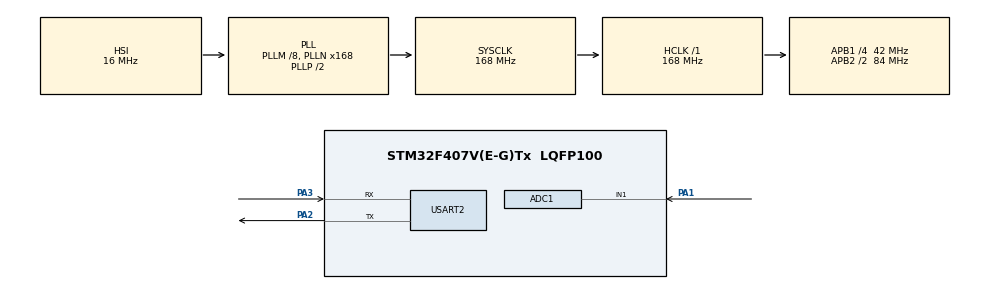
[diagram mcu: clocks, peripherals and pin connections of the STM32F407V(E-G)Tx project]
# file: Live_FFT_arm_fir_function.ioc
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ADC1.Channel-5\#ChannelRegularConversion=ADC_CHANNEL_1
ADC1.ContinuousConvMode=DISABLE
ADC1.NbrOfConversionFlag=1
ADC1.Rank-5\#ChannelRegularConversion=1
ADC1.SamplingTime-5\#ChannelRegularConversion=ADC_SAMPLETIME_3CYCLES
ADC1.master=1
Mcu.Family=STM32F4
Mcu.Name=STM32F407V(E-G)Tx
Mcu.Package=LQFP100
NVIC.PriorityGroup=NVIC_PRIORITYGROUP_0
PA1.Signal=ADCx_IN1
PA2.Mode=Asynchronous
PA2.Signal=USART2_TX
PA3.Mode=Asynchronous
PA3.Signal=USART2_RX
PH0-OSC_IN.Mode=HSE-External-Oscillator
PH0-OSC_IN.Signal=RCC_OSC_IN
PH1-OSC_OUT.Mode=HSE-External-Oscillator
PH1-OSC_OUT.Signal=RCC_OSC_OUT
ProjectManager.HeapSize=0x200
ProjectManager.StackSize=0x400
ProjectManager.TargetToolchain=STM32CubeIDE
RCC.48MHZClocksFreq_Value=48000000
RCC.AHBFreq_Value=168000000
RCC.APB1CLKDivider=RCC_HCLK_DIV4
RCC.APB1Freq_Value=42000000
RCC.APB1TimFreq_Value=84000000
RCC.APB2CLKDivider=RCC_HCLK_DIV2
RCC.APB2Freq_Value=84000000
RCC.APB2TimFreq_Value=168000000
RCC.CortexFreq_Value=168000000
RCC.HCLKFreq_Value=168000000
RCC.HSE_VALUE=8000000
RCC.HSI_VALUE=16000000
RCC.LSE_VALUE=32768
RCC.PLLM=8
RCC.PLLN=168
RCC.PLLQ=7
RCC.SYSCLKFreq_VALUE=168000000
RCC.SYSCLKSource=RCC_SYSCLKSOURCE_PLLCLK
RCC.VCOOutputFreq_Value=336000000
SH.ADCx_IN1.0=ADC1_IN1,IN1
USART2.VirtualMode=VM_ASYNC
board=STM32F407G-DISC1

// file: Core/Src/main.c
/* USER CODE BEGIN Header */
/**
  ******************************************************************************
  * @file           : main.c
  * @brief          : Main program body
  ******************************************************************************
  * @attention
  *
  * Copyright (c) 2026 STMicroelectronics.
  * All rights reserved.
  *
  * This software is licensed under terms that can be found in the LICENSE file
  * in the root directory of this software component.
  * If no LICENSE file comes with this software, it is provided AS-IS.
  *
  ******************************************************************************
  */
/* USER CODE END Header */
#include "main.h"
#include "adc.h"
#include "usart.h"
#include "gpio.h"

/* USER CODE BEGIN Includes */
//#include "stm32f407xx.h"
#include "signals.h"
#include "stdio.h"
#include "arm_math.h"
#include <math.h>
#include "stdlib.h"
#include "fifo.h"
/* USER CODE END Includes */

/* USER CODE BEGIN PTD */

#define FILTER_Taps fir_len

/* ===== ARM fir_function ===== */
#define NUM_TAPS   fir_len
#define BLOCK_SIZE live_ecg_len

arm_fir_instance_f32 firFilter;
float32_t firState[NUM_TAPS + BLOCK_SIZE - 1];
/* ========================== */

#define input_sig_len live_ecg_len
#define filter_len fir_len

extern const float32_t  _640_points_ecg_[sig_ecg_len];
extern const float32_t ecg_mudy_sig[ECG_mudy_len];
extern const float32_t fir_filter[fir_len];

extern volatile uint8_t sample_tick;

/* ---- Compile-time "round up to next power of two" -------------------------
 * Classic bit-smearing trick: OR each bit down into all bits below it, then
 * add 1. Works purely with constant arithmetic, so the result can be used
 * as an array size. */
#define _B2(x)   ( (x)      | ((x) >> 1)  )
#define _B4(x)   ( _B2(x)   | (_B2(x) >> 2)  )
#define _B8(x)   ( _B4(x)   | (_B4(x) >> 4)  )
#define _B16(x)  ( _B8(x)   | (_B8(x) >> 8)  )
#define _B32(x)  ( _B16(x)  | (_B16(x) >> 16) )
#define NEXT_POW2(x)  (_B32((x) - 1) + 1)

/* ===== OR ===== */

//uint32_t next_power_of_2(uint32_t x)
//{
//    if (x == 0) return 1;
//
//    x = x - 1;          // step 1: back off by one (so exact powers of 2 stay unchanged)
//
//    // step 2: "smear" the highest set bit downward into every bit below it,
//    // by repeatedly OR-ing the number with a right-shifted copy of itself
//    x = x | (x >> 1);
//    x = x | (x >> 2);
//    x = x | (x >> 4);
//    x = x | (x >> 8);
//    x = x | (x >> 16);
//    // at this point x is all 1-bits, e.g. 0b00011111 (31)
//
//    x = x + 1;           // step 3: turn "all 1s" into the actual power of two
//
//    return x;
//}

/* Length needed for a full ("linear") convolution of the ECG signal with the
 * FIR filter: len(x) + len(h) - 1.
 *
 * NOTE: renamed from the original "L" to "LINEAR_CONV_LEN". A macro named
 * "L" would have been substituted INSIDE the prototype
 * "uint32_t next_power_of_2(uint32_t L)" below, mangling the parameter name -
 * a subtle bug waiting to happen even after fixing the file-scope issue. */
#define LINEAR_CONV_LEN  (input_sig_len + filter_len - 1)

/* Smallest power-of-two FFT length that can hold the full linear convolution
 * without circular-convolution wrap-around (this is a classic
 * overlap-save / fast-convolution-via-FFT length requirement). Computed at
 * compile time now - no more runtime "fft_len" needed for sizing. */
#define FFT_BUFFER_SIZE  NEXT_POW2(LINEAR_CONV_LEN)

/* arm_rfft_fast_f32 (CMSIS-DSP, f32 variant) only supports power-of-two
 * lengths from 32 to 4096. Catch an unsupported combination of signal /
 * filter lengths at BUILD time instead of arm_rfft_fast_init_f32() silently
 * returning an error status at runtime. */
//#if (FFT_BUFFER_SIZE < 32) || (FFT_BUFFER_SIZE > 4096)
//#error "FFT_BUFFER_SIZE is outside the range supported by arm_rfft_fast_f32 (32-4096). Check input_sig_len/filter_len in signals.h."
//#endif

float32_t padded_filter[FFT_BUFFER_SIZE];
float32_t padded_filter2[FFT_BUFFER_SIZE];
float32_t FFT_Buff_In[FFT_BUFFER_SIZE];
float32_t FFT_Buff_In2[FFT_BUFFER_SIZE];
float32_t FFT_Buff_Out[FFT_BUFFER_SIZE];
float32_t FFT_Buff_Out_original[LINEAR_CONV_LEN];
float32_t conv_out[LINEAR_CONV_LEN];
float32_t conv_out_aligned[input_sig_len];   /* group-delay-compensated, same length as input */

float32_t fft_time_result[FFT_BUFFER_SIZE];

#define GROUP_DELAY  ((filter_len - 1) / 2)

/* Time-aligned filtered output: FFT_Buff_Out_original[n + GROUP_DELAY] is
 * what actually corresponds to input sample n, once the filter's inherent
 * delay is removed. Same length as the input signal, so it plots directly
 * against ecg_mudy_sig sample-for-sample with no offset. */
float32_t FFT_Buff_Out_aligned[input_sig_len];
/* USER CODE END PTD */

/* USER CODE BEGIN PD */

void plot_signal(float32_t *arr,uint32_t sign_len);
arm_rfft_fast_instance_f32 fftHandler;

static uint16_t format_sample(float32_t sample, char *dst, uint16_t dst_size);
void plot_signal_2(float32_t *arr1, uint32_t len1, float32_t *arr2, uint32_t len2);
 void plot_signal_3(float32_t *arr1, uint32_t len1, float32_t *arr2, uint32_t len2,float32_t *arr3, uint32_t len3);

/* USER CODE END PD */

void SystemClock_Config(void);

/* USER CODE BEGIN 0 */

/* ===== Fifo variables ===== */
volatile uint8_t  flag = 0;
uint32_t sample_count = 0;
volatile uint32_t fifo_overflow_count = 0;   /* FIFO was full when a sample arrived */
volatile uint32_t adc_timeout_count   = 0;   /* ADC didn't finish converting in time */

uint16_t val = 0; //rx_DataType
rx_DataType rx_data;
#define adc_buff_len 500
rx_DataType adc_buff[adc_buff_len];   /* same type as the FIFO holds */

uint32_t adc_ready = 0;
char bf[10];
/* ===== END ===== */

void reduce_to_original_len(float32_t *output_buff)
{
    for (uint32_t i = 0; i < LINEAR_CONV_LEN; i++)
	{
        FFT_Buff_Out_original[i] = output_buff[i];
	}
}
/* ===== Systick CallBack ===== */
//void HAL_SYSTICK_Callback(void)
//{
//	if(!adc_ready)
//	{
//		return;
//	}
//    if (HAL_ADC_Start(&hadc1) != HAL_OK)
//    {
//        return;
//    }
//
//    if (HAL_ADC_PollForConversion(&hadc1, 1) == HAL_OK)
//    {
//        val = (rx_DataType)HAL_ADC_GetValue(&hadc1);
//
//        if (rx_fifo_put(val) == RXFIFO_Done)
//        {
//            sample_count++;
//            if (sample_count >= adc_buff_len)
//            {
//                flag = 1;
//                sample_count = 0;
//            }
//        }
//        else
//        {
//            fifo_overflow_count++;   /* main loop is draining too slowly */
//        }
//    }
//    else
//    {
//        adc_timeout_count++;         /* diagnostic only — should stay 0 */
//    }
//}
/* ===== END ===== */
float32_t block_in[BLOCK_SIZE], block_out[BLOCK_SIZE];
volatile float32_t swv_fir_sample;
/* USER CODE END 0 */

int main(void)
{

  /* MCU Configuration--------------------------------------------------------*/

  /* Reset of all peripherals, Initializes the Flash interface and the Systick. */
  HAL_Init();

  /* Configure the system clock */
  SystemClock_Config();

  /* Initialize all configured peripherals */
  MX_GPIO_Init();
  MX_USART2_UART_Init();
  MX_ADC1_Init();
  /* USER CODE BEGIN 2 */

  rx_fifo_init();

  /* USER CODE END 2 */

  /* Infinite loop */
  /* USER CODE BEGIN WHILE */

  //HAL_ADC_Start_IT(&hadc1);

      adc_ready = 1;

 arm_fir_init_f32(&firFilter, NUM_TAPS, (float32_t *)fir_filter, firState, BLOCK_SIZE);

  while (1)
  {
    /* USER CODE END WHILE */

    /* USER CODE BEGIN 3 */
	  if(sample_tick)
	  {
		  sample_tick = 0;

	        if (HAL_ADC_Start(&hadc1) == HAL_OK &&
	            HAL_ADC_PollForConversion(&hadc1, 1) == HAL_OK)
	        {
	            val = (rx_DataType)HAL_ADC_GetValue(&hadc1);
	            if (rx_fifo_put(val) == RXFIFO_Done)
	            {
	                sample_count++;
	                if (sample_count >= adc_buff_len)
	                {
	                    flag = 1;
	                    sample_count = 0;
	                }
	            }
	            else { fifo_overflow_count++; }
	        }
	        else { adc_timeout_count++; }

	  }
	  /* ===== ADC buffer fill ===== */

	  if (flag == 1)
	 	      {
	 	          int received = 0;

	 	          for (int i = 0; i < adc_buff_len; i++)
	 	          {
	 	              if (rx_fifo_get(&rx_data) == RXFIFO_Done)
	 	              {
	 	                  adc_buff[i] = rx_data;
	 	                  received++;
	 	              }
	 	              else
	 	              {
	 	                  break;
	 	              }
	 	          }

//	 	          for (int i = 0; i < received; i++)
//	 	          {
//	 	              sprintf(bf, "%d\r\n", adc_buff[i]);
//	 	              HAL_UART_Transmit(&huart2, (uint8_t *)bf, strlen(bf), HAL_MAX_DELAY);
//	 	          }

	 	        for (uint32_t i = 0; i < BLOCK_SIZE; i++)

	 	        	{
	 	        	block_in[i] = (float32_t)adc_buff[i];
	 	        	}

	 	        arm_fir_f32(&firFilter,block_in,block_out,BLOCK_SIZE);

//for(int j = 0;j<BLOCK_SIZE;j++)
//{
//	swv_fir_sample = block_out[j];
//}
		          /* ===== Plotting ===== */
	 	       for (uint32_t i = 0; i < BLOCK_SIZE; i++)
	 	              {
	 	                  char tx_buf[128];

	 	                  snprintf(
	 	                      tx_buf,
	 	                      sizeof(tx_buf),
	 	                      "%.5f,%.5f\r\n",
	 	                      block_in[i],
	 	                      block_out[i]
	 	                  );

	 	                  HAL_UART_Transmit(
	 	                      &huart2,
	 	                      (uint8_t *)tx_buf,
	 	                      strlen(tx_buf),
	 	                      HAL_MAX_DELAY
	 	                  );
	 	              }

	 	            // plot_signal((float32_t*)adc_buff,adc_buff_len);
		           // plot_signal_2((float32_t*)adc_buff, adc_buff_len,block_out ,BLOCK_SIZE );
		         // plot_signal_3(ecg_mudy_sig, input_sig_len, conv_out_aligned,input_sig_len,FFT_Buff_Out_aligned, input_sig_len );

	 	          flag = 0;
	 	      }
	 	    }

	  /* ===== ADC Testing Code ===== */

//	  HAL_ADC_Start(&hadc1);
//	  HAL_ADC_PollForConversion(&hadc1, 1);
//	  val = HAL_ADC_GetValue(&hadc1);
//      sprintf(bf, "%d\r\n", val);
//      HAL_UART_Transmit(&huart2, (uint8_t *)bf, strlen(bf), HAL_MAX_DELAY);

	 /* ===== END ===== */

  /* USER CODE END 3 */
}

void SystemClock_Config(void)
{
  RCC_OscInitTypeDef RCC_OscInitStruct = {0};
  RCC_ClkInitTypeDef RCC_ClkInitStruct = {0};

  /** Configure the main internal regulator output voltage
  */
  __HAL_RCC_PWR_CLK_ENABLE();
  __HAL_PWR_VOLTAGESCALING_CONFIG(PWR_REGULATOR_VOLTAGE_SCALE1);

  /** Initializes the RCC Oscillators according to the specified parameters
  * in the RCC_OscInitTypeDef structure.
  */
  RCC_OscInitStruct.OscillatorType = RCC_OSCILLATORTYPE_HSI;
  RCC_OscInitStruct.HSIState = RCC_HSI_ON;
  RCC_OscInitStruct.HSICalibrationValue = RCC_HSICALIBRATION_DEFAULT;
  RCC_OscInitStruct.PLL.PLLState = RCC_PLL_ON;
  RCC_OscInitStruct.PLL.PLLSource = RCC_PLLSOURCE_HSI;
  RCC_OscInitStruct.PLL.PLLM = 8;
  RCC_OscInitStruct.PLL.PLLN = 168;
  RCC_OscInitStruct.PLL.PLLP = RCC_PLLP_DIV2;
  RCC_OscInitStruct.PLL.PLLQ = 7;
  if (HAL_RCC_OscConfig(&RCC_OscInitStruct) != HAL_OK)
  {
    Error_Handler();
  }

  /** Initializes the CPU, AHB and APB buses clocks
  */
  RCC_ClkInitStruct.ClockType = RCC_CLOCKTYPE_HCLK|RCC_CLOCKTYPE_SYSCLK
                              |RCC_CLOCKTYPE_PCLK1|RCC_CLOCKTYPE_PCLK2;
  RCC_ClkInitStruct.SYSCLKSource = RCC_SYSCLKSOURCE_PLLCLK;
  RCC_ClkInitStruct.AHBCLKDivider = RCC_SYSCLK_DIV1;
  RCC_ClkInitStruct.APB1CLKDivider = RCC_HCLK_DIV4;
  RCC_ClkInitStruct.APB2CLKDivider = RCC_HCLK_DIV2;

  if (HAL_RCC_ClockConfig(&RCC_ClkInitStruct, FLASH_LATENCY_5) != HAL_OK)
  {
    Error_Handler();
  }
}

/* USER CODE BEGIN 4 */
void plot_signal(float32_t *arr, uint32_t sig_len)
{
    char tx_buf[32];
    uint16_t len;

   // sig_len = sig_len / 2;

    for (uint32_t i = 0; i < sig_len; i++)
    {
        long val = (long)(arr[i] * 100000.0f);
        long int_part  = val / 100000;
        long frac_part = labs(val % 100000);

        if (val < 0 && int_part == 0) {
            len = snprintf(tx_buf, sizeof(tx_buf), "-%ld.%05ld\r\n", int_part, frac_part);
        } else {
            len = snprintf(tx_buf, sizeof(tx_buf), "%ld.%05ld\r\n", int_part, frac_part);
        }

        HAL_UART_Transmit(&huart2, (uint8_t*)tx_buf, len, HAL_MAX_DELAY);
        HAL_Delay(50);
    }
}
static uint16_t format_sample(float32_t sample, char *dst, uint16_t dst_size)
{
    long val = (long)(sample * 100000.0f);
    long int_part  = val / 100000;
    long frac_part = labs(val % 100000);

    if (val < 0 && int_part == 0) {
        return snprintf(dst, dst_size, "-%ld.%05ld", int_part, frac_part);
    } else {
        return snprintf(dst, dst_size, "%ld.%05ld", int_part, frac_part);
    }
}
void plot_signal_2(float32_t *arr1, uint32_t len1, float32_t *arr2, uint32_t len2)
{
    char tx_buf[40];
    char val_buf[16];
    uint16_t len;
    uint32_t max_len = (len1 > len2) ? len1 : len2;

    for (uint32_t i = 0; i < max_len; i++)
    {
        if (i < len1) {
            format_sample(arr1[i], val_buf, sizeof(val_buf));
        } else {
            val_buf[0] = '\0';   // ran out of samples for signal 1 - leave blank
        }
        len = snprintf(tx_buf, sizeof(tx_buf), "%s,", val_buf);

        if (i < len2) {
            format_sample(arr2[i], val_buf, sizeof(val_buf));
        } else {
            val_buf[0] = '\0';   // ran out of samples for signal 2 - leave blank
        }
        len += snprintf(tx_buf + len, sizeof(tx_buf) - len, "%s\r\n", val_buf);

        HAL_UART_Transmit(&huart2, (uint8_t*)tx_buf, len, HAL_MAX_DELAY);
        HAL_Delay(50);
    }
}
void plot_signal_3(float32_t *arr1, uint32_t len1,
                  float32_t *arr2, uint32_t len2,
                  float32_t *arr3, uint32_t len3)
{
    char tx_buf[80];
    char val_buf[24];
    uint16_t len;

    uint32_t max_len = len1;

    if (len2 > max_len)
        max_len = len2;

    if (len3 > max_len)
        max_len = len3;

    for (uint32_t i = 0; i < max_len; i++)
    {
        len = 0;

        /* Signal 1 */
        if (i < len1)
        {
            format_sample(arr1[i], val_buf, sizeof(val_buf));
            len += snprintf(tx_buf + len,
                            sizeof(tx_buf) - len,
                            "%s,", val_buf);
        }

        /* Signal 2 */
        if (i < len2)
        {
            format_sample(arr2[i], val_buf, sizeof(val_buf));
            len += snprintf(tx_buf + len,
                            sizeof(tx_buf) - len,
                            "%s,", val_buf);
        }

        /* Signal 3 */
        if (i < len3)
        {
            format_sample(arr3[i], val_buf, sizeof(val_buf));
            len += snprintf(tx_buf + len,
                            sizeof(tx_buf) - len,
                            "%s", val_buf);
        }

        /* New line */
        len += snprintf(tx_buf + len,
                        sizeof(tx_buf) - len,
                        "\r\n");

        HAL_UART_Transmit(&huart2,
                          (uint8_t *)tx_buf,
                          len,
                          HAL_MAX_DELAY);

        HAL_Delay(50);
    }
}

/* USER CODE END 4 */

void Error_Handler(void)
{
  __disable_irq();
  while (1)
  {
  }
}
